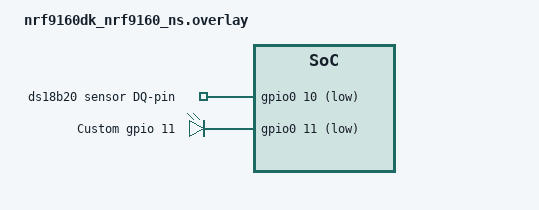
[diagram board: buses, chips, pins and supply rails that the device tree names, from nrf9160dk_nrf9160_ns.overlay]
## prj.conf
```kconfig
# nothing here
CONFIG_GPIO=y
CONFIG_CBPRINTF_FP_SUPPORT=y
```

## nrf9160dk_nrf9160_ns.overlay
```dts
// To get started, press Ctrl+Space to bring up the completion menu and view the available nodes.
// For more help, browse the DeviceTree documentation at https://docs.zephyrproject.org/latest/guides/dts/index.html
/ {
    gpiocustom {
        compatible = "gpio-leds";
        gpiocus10: gpiocus_10 {
            gpios = <&gpio0 10 (GPIO_PULL_UP | GPIO_ACTIVE_LOW)>; 
            label = "ds18b20 sensor DQ-pin";
        };
        gpiocus11: gpiocus11 {
            gpios = <&gpio0 11 GPIO_ACTIVE_LOW>;
            label = "Custom gpio 11";
        };
    };
    aliases {
        gpiocus10 = &gpiocus10;
        gpiocus11 = &gpiocus11;
    };
};
```

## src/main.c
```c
#include <zephyr.h>
#include <math.h>
#include <stdio.h>
#include <stdlib.h>
#include <device.h>
#include <devicetree.h>
#include <sys/printk.h>
#include <drivers/gpio.h>
#include <drivers/sensor.h>
#include <kernel.h>
#include <logging/log.h>
#include <sys/__assert.h>

#include "ds18b20.h"



void main(void){

	printk("DS18b20 sensor test program started on %s-ns\n", CONFIG_BOARD);
	//k_msleep(5000);

	Init_GPIO();
  gpio_pin_configure(gpio_dev, 11, GPIO_OUTPUT);
	
	while(true){
		printf("read temp: %0.8f \r\n", ds18b20_read_temp());
    
		gpio_pin_set(gpio_dev, 11, 1);
		k_msleep(500);
		gpio_pin_set(gpio_dev, 11, 0);
    k_msleep(500);

		
	}
}
```

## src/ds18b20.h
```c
#define DQ_PIN 10
static const struct device *gpio_dev;


void Init_GPIO(){

    gpio_dev = device_get_binding("GPIO_0");
    if (!gpio_dev) {
	    printk("Error getting GPIO_0: failed.\n");
    }

}


void ds18b20_read(void * data_ptr, unsigned int num_bytes){
  char  ch; //Current reading byte buffer
  char * data_buf = data_ptr;
  
  int i=0,u=0;
  for (i=0;i<num_bytes;i++){
    ch=0;
    for(u=0;u<8;u++){
      //Form read slot
      gpio_pin_configure(gpio_dev, DQ_PIN, GPIO_OUTPUT);
      gpio_pin_set(gpio_dev, DQ_PIN, 0);
      k_busy_wait(5);
      gpio_pin_configure(gpio_dev, DQ_PIN, GPIO_INPUT);
      k_busy_wait(10);
      if(gpio_pin_get_raw(gpio_dev, DQ_PIN)!=0){
        ch |= 1 << u; //There is 1 on the bus
      }
      else{
        ch &= ~(1 << u); //There us 0 on the bus
      }

      //Apply "long" timer for make sure that timeslot is end
     k_busy_wait(60);
    }
    data_buf[i]=ch;
  }
 	gpio_pin_configure(gpio_dev, DQ_PIN, GPIO_INPUT);
}

/* Function to write byte*/
void ds18b20_write(void * data_ptr, unsigned int num_bytes){
  char  ch; //Current reading byte buffer
  char * data_buf = data_ptr;
  
  int i=0,u=0;
  for (i=0;i<num_bytes;i++){
    ch=data_buf[i];
    for(u=0;u<8;u++){
      //Form write slot
      gpio_pin_configure(gpio_dev, DQ_PIN, GPIO_OUTPUT);
	    gpio_pin_set(gpio_dev, DQ_PIN, 0);
      k_busy_wait(1);;
      //write 1 - pull bus to HIGH just after short timer
      if(ch&(1<<u)){
		    gpio_pin_configure(gpio_dev, DQ_PIN, GPIO_INPUT);
      }
      //Apply "long" timer for make sure that timeslot is end
      k_busy_wait(60);
      //Release bus, if this wasn't done before
	    gpio_pin_configure(gpio_dev, DQ_PIN, GPIO_INPUT);
      data_buf[i]=ch;
    }
  }
  gpio_pin_configure(gpio_dev, DQ_PIN, GPIO_INPUT);
}


//Perform reset of the bus, and then wait for the presence pulse
bool ds18b20_reset_and_check(void){
  int res=0;
  //Form reset pulse
  
  gpio_pin_configure(gpio_dev, DQ_PIN, GPIO_OUTPUT);
  gpio_pin_set(gpio_dev, DQ_PIN, 0);
  k_busy_wait(500);
  //Release bus and wait 15-60MS
  gpio_pin_configure(gpio_dev, DQ_PIN, GPIO_INPUT);
  k_busy_wait(60);

  //Read from bus
  res=gpio_pin_get_raw(gpio_dev, DQ_PIN);
  if(res==0){
    k_busy_wait(500);
    return true;
  }
  return false;
}


float ds18b20_read_temp(void){
   char buf[16];
    double temp;
        //int i;
     int16_t raw_temp=0;

    ds18b20_reset_and_check();

//Read ROM
    buf[0]=0x33;
    ds18b20_write(&buf,1);

//Read the results
    
    ds18b20_read(&buf,8);
    memset(&buf,0,16);

    //Send convert TX cmd
    buf[0]=0x44; //Convert temp
    ds18b20_write(&buf,1);
    k_busy_wait(1000000);//Wait for finishing of the conversion

    ds18b20_reset_and_check();
    buf[0]=0x33; //Read ROM
    ds18b20_write(&buf,1);
    //Read the results
    ds18b20_read(&buf,8);
    memset(&buf,0,16);
    buf[0]=0xBE;  //Read scratchpad
    ds18b20_write(&buf,1);
    //Read the results
    ds18b20_read(&buf,12);
    raw_temp = (buf[1] << 8) | buf[0];

    //memcpy(&f,&buf,8);
    temp = (float)raw_temp / 16.0;
    return(temp);
}
```
